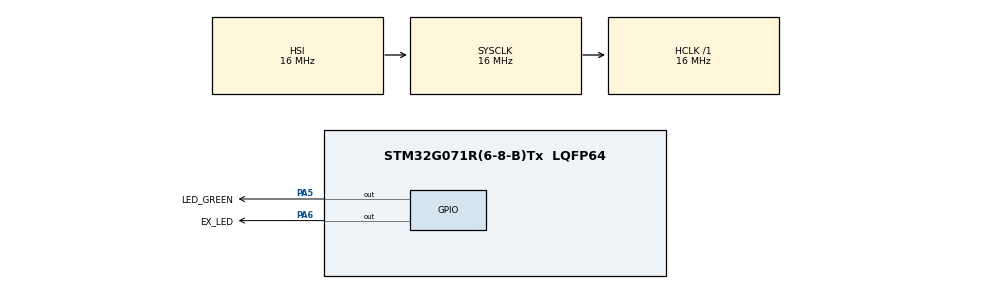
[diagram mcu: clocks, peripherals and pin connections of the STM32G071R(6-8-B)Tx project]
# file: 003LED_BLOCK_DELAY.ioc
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Mcu.Family=STM32G0
Mcu.Name=STM32G071R(6-8-B)Tx
Mcu.Package=LQFP64
NVIC.TIM6_DAC_LPTIM1_IRQn=true\:3\:0\:false\:false\:true\:false\:true
NVIC.TimeBase=TIM6_DAC_LPTIM1_IRQn
NVIC.TimeBaseIP=TIM6
PA13.GPIO_Label=TMS
PA13.Signal=SYS_SWDIO
PA14-BOOT0.GPIO_Label=TCK
PA14-BOOT0.Signal=SYS_SWCLK
PA2.GPIO_Label=USART2_TX [STLK_TX]
PA2.Signal=USART2_TX
PA3.GPIO_Label=USART2_RX [STLK_RX]
PA3.Signal=USART2_RX
PA5.GPIO_Label=LED_GREEN
PA5.GPIO_Speed=GPIO_SPEED_FREQ_HIGH
PA5.Signal=GPIO_Output
PA6.GPIO_Label=EX_LED
PA6.Signal=GPIO_Output
PC13.Signal=SYS_WKUP2
PC14-OSC32_IN\ (PC14).Signal=RCC_OSC32_IN
PC15-OSC32_OUT\ (PC15).Signal=RCC_OSC32_OUT
PF0-OSC_IN\ (PF0).GPIO_Label=MCO
PF0-OSC_IN\ (PF0).Signal=RCC_OSC_IN
ProjectManager.HeapSize=0x200
ProjectManager.StackSize=0x400
ProjectManager.TargetToolchain=STM32CubeIDE
RCC.AHBFreq_Value=16000000
RCC.CortexFreq_Value=16000000
RCC.EXTERNAL_CLOCK_VALUE=12288000
RCC.HCLKFreq_Value=16000000
RCC.HSE_VALUE=8000000
RCC.HSI_VALUE=16000000
RCC.LSE_VALUE=32768
RCC.SYSCLKFreq_VALUE=16000000
RCC.VCOOutputFreq_Value=128000000
VP_SYS_VS_DBSignals.Mode=DisableDeadBatterySignals
VP_SYS_VS_tim6.Mode=TIM6
board=NUCLEO-G071RB

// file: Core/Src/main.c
/* USER CODE BEGIN Header */
/**
  ******************************************************************************
  * @file           : main.c
  * @brief          : Main program body
  ******************************************************************************
  * @attention
  *
  * <h2><center>&copy; Copyright (c) 2023 STMicroelectronics.
  * All rights reserved.</center></h2>
  *
  * This software component is licensed by ST under BSD 3-Clause license,
  * the "License"; You may not use this file except in compliance with the
  * License. You may obtain a copy of the License at:
  *                        opensource.org/licenses/BSD-3-Clause
  *
  ******************************************************************************
  */
/* USER CODE END Header */
#include "main.h"

/* USER CODE BEGIN Includes */
#include "FreeRTOS.h"
#include "task.h"
/* USER CODE END Includes */

void SystemClock_Config(void);
static void MX_GPIO_Init(void);
/* USER CODE BEGIN PFP */

static void Taskfunc1(void *parameters);
static void Taskfunc2(void *parameters);

/* USER CODE END PFP */

int main(void)
{
  /* USER CODE BEGIN 1 */

	TaskHandle_t task1_handle;
	TaskHandle_t task2_handle;

	BaseType_t status;

  /* USER CODE END 1 */

  /* MCU Configuration--------------------------------------------------------*/

  /* Reset of all peripherals, Initializes the Flash interface and the Systick. */
  HAL_Init();

  /* Configure the system clock */
  SystemClock_Config();

  /* Initialize all configured peripherals */
  MX_GPIO_Init();
  /* USER CODE BEGIN 2 */

  status = xTaskCreate(Taskfunc1,"Task-1",200,NULL,2,&task1_handle);
  configASSERT(status = pdPASS);

  status = xTaskCreate(Taskfunc2,"Task-2",200,NULL,2,&task2_handle);
  configASSERT(status = pdPASS);

  vTaskStartScheduler();

  /* USER CODE END 2 */

  /* Infinite loop */
  while (1)
  {

  }
}

void SystemClock_Config(void)
{
  RCC_OscInitTypeDef RCC_OscInitStruct = {0};
  RCC_ClkInitTypeDef RCC_ClkInitStruct = {0};

  /** Configure the main internal regulator output voltage
  */
  HAL_PWREx_ControlVoltageScaling(PWR_REGULATOR_VOLTAGE_SCALE1);
  /** Initializes the RCC Oscillators according to the specified parameters
  * in the RCC_OscInitTypeDef structure.
  */
  RCC_OscInitStruct.OscillatorType = RCC_OSCILLATORTYPE_HSI;
  RCC_OscInitStruct.HSIState = RCC_HSI_ON;
  RCC_OscInitStruct.HSIDiv = RCC_HSI_DIV1;
  RCC_OscInitStruct.HSICalibrationValue = RCC_HSICALIBRATION_DEFAULT;
  RCC_OscInitStruct.PLL.PLLState = RCC_PLL_NONE;
  if (HAL_RCC_OscConfig(&RCC_OscInitStruct) != HAL_OK)
  {
    Error_Handler();
  }
  /** Initializes the CPU, AHB and APB buses clocks
  */
  RCC_ClkInitStruct.ClockType = RCC_CLOCKTYPE_HCLK|RCC_CLOCKTYPE_SYSCLK
                              |RCC_CLOCKTYPE_PCLK1;
  RCC_ClkInitStruct.SYSCLKSource = RCC_SYSCLKSOURCE_HSI;
  RCC_ClkInitStruct.AHBCLKDivider = RCC_SYSCLK_DIV1;
  RCC_ClkInitStruct.APB1CLKDivider = RCC_HCLK_DIV1;

  if (HAL_RCC_ClockConfig(&RCC_ClkInitStruct, FLASH_LATENCY_0) != HAL_OK)
  {
    Error_Handler();
  }
}

static void MX_GPIO_Init(void)
{
  GPIO_InitTypeDef GPIO_InitStruct = {0};

  /* GPIO Ports Clock Enable */
  __HAL_RCC_GPIOC_CLK_ENABLE();
  __HAL_RCC_GPIOF_CLK_ENABLE();
  __HAL_RCC_GPIOA_CLK_ENABLE();

  /*Configure GPIO pin Output Level */
  HAL_GPIO_WritePin(GPIOA, LED_GREEN_Pin|EX_LED_Pin, GPIO_PIN_RESET);

  /*Configure GPIO pins : USART2_TX_Pin USART2_RX_Pin */
  GPIO_InitStruct.Pin = USART2_TX_Pin|USART2_RX_Pin;
  GPIO_InitStruct.Mode = GPIO_MODE_AF_PP;
  GPIO_InitStruct.Pull = GPIO_NOPULL;
  GPIO_InitStruct.Speed = GPIO_SPEED_FREQ_LOW;
  GPIO_InitStruct.Alternate = GPIO_AF1_USART2;
  HAL_GPIO_Init(GPIOA, &GPIO_InitStruct);

  /*Configure GPIO pin : LED_GREEN_Pin */
  GPIO_InitStruct.Pin = LED_GREEN_Pin;
  GPIO_InitStruct.Mode = GPIO_MODE_OUTPUT_PP;
  GPIO_InitStruct.Pull = GPIO_NOPULL;
  GPIO_InitStruct.Speed = GPIO_SPEED_FREQ_HIGH;
  HAL_GPIO_Init(LED_GREEN_GPIO_Port, &GPIO_InitStruct);

  /*Configure GPIO pin : EX_LED_Pin */
  GPIO_InitStruct.Pin = EX_LED_Pin;
  GPIO_InitStruct.Mode = GPIO_MODE_OUTPUT_PP;
  GPIO_InitStruct.Pull = GPIO_NOPULL;
  GPIO_InitStruct.Speed = GPIO_SPEED_FREQ_LOW;
  HAL_GPIO_Init(EX_LED_GPIO_Port, &GPIO_InitStruct);

}

/* USER CODE BEGIN 4 */

static void Taskfunc1(void *parameters)
{
	while(1)
	{
		HAL_GPIO_TogglePin(EX_LED_GPIO_Port, EX_LED_Pin);
		vTaskDelay(pdMS_TO_TICKS(1000));
	}
}

static void Taskfunc2(void *parameters)
{
	while(1)
	{
		HAL_GPIO_TogglePin(LED_GREEN_GPIO_Port, LED_GREEN_Pin);
		vTaskDelay(pdMS_TO_TICKS(5000));
	}
}
/* USER CODE END 4 */

void HAL_TIM_PeriodElapsedCallback(TIM_HandleTypeDef *htim)
{
  if (htim->Instance == TIM6) {
    HAL_IncTick();
  }
}

void Error_Handler(void)
{
  __disable_irq();
  while (1)
  {
  }
}

/************************ (C) COPYRIGHT STMicroelectronics *****END OF FILE****/
